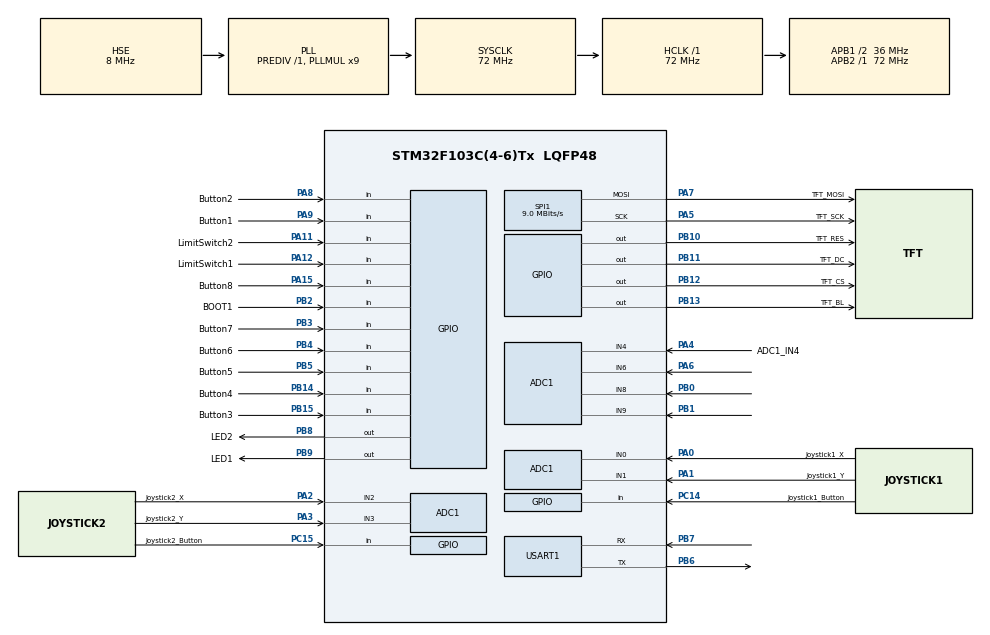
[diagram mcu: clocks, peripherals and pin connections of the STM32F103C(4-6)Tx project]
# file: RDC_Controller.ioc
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ADC1.Channel-0\#ChannelRegularConversion=ADC_CHANNEL_0
ADC1.Channel-1\#ChannelRegularConversion=ADC_CHANNEL_1
ADC1.Channel-2\#ChannelRegularConversion=ADC_CHANNEL_2
ADC1.Channel-3\#ChannelRegularConversion=ADC_CHANNEL_3
ADC1.ContinuousConvMode=ENABLE
ADC1.NbrOfConversion=4
ADC1.NbrOfConversionFlag=1
ADC1.Rank-0\#ChannelRegularConversion=1
ADC1.Rank-1\#ChannelRegularConversion=2
ADC1.Rank-2\#ChannelRegularConversion=3
ADC1.Rank-3\#ChannelRegularConversion=4
ADC1.SamplingTime-0\#ChannelRegularConversion=ADC_SAMPLETIME_1CYCLE_5
ADC1.SamplingTime-1\#ChannelRegularConversion=ADC_SAMPLETIME_1CYCLE_5
ADC1.SamplingTime-2\#ChannelRegularConversion=ADC_SAMPLETIME_1CYCLE_5
ADC1.SamplingTime-3\#ChannelRegularConversion=ADC_SAMPLETIME_1CYCLE_5
ADC1.master=1
Dma.ADC1.0.Direction=DMA_PERIPH_TO_MEMORY
Dma.ADC1.0.Instance=DMA1_Channel1
Dma.ADC1.0.MemDataAlignment=DMA_MDATAALIGN_HALFWORD
Dma.ADC1.0.MemInc=DMA_MINC_ENABLE
Dma.ADC1.0.Mode=DMA_CIRCULAR
Dma.ADC1.0.PeriphDataAlignment=DMA_PDATAALIGN_HALFWORD
Dma.ADC1.0.PeriphInc=DMA_PINC_DISABLE
Dma.ADC1.0.Priority=DMA_PRIORITY_HIGH
Dma.Request0=ADC1
Mcu.Family=STM32F1
Mcu.Name=STM32F103C(4-6)Tx
Mcu.Package=LQFP48
NVIC.PriorityGroup=NVIC_PRIORITYGROUP_4
NVIC.USART1_IRQn=true\:1\:0\:true\:false\:true\:true\:true\:true
PA0-WKUP.GPIO_Label=Joystick1_X
PA0-WKUP.Signal=ADCx_IN0
PA1.GPIO_Label=Joystick1_Y
PA1.Signal=ADCx_IN1
PA11.GPIO_Label=LimitSwitch2
PA11.GPIO_PuPd=GPIO_NOPULL
PA11.Signal=GPIO_Input
PA12.GPIO_Label=LimitSwitch1
PA12.GPIO_PuPd=GPIO_NOPULL
PA12.Signal=GPIO_Input
PA13.Mode=Serial_Wire
PA13.Signal=SYS_JTMS-SWDIO
PA14.Mode=Serial_Wire
PA14.Signal=SYS_JTCK-SWCLK
PA15.GPIO_Label=Button8
PA15.GPIO_PuPd=GPIO_PULLUP
PA15.Signal=GPIO_Input
PA2.GPIO_Label=Joystick2_X
PA2.Signal=ADCx_IN2
PA3.GPIO_Label=Joystick2_Y
PA3.Signal=ADCx_IN3
PA4.GPIO_Label=ADC1_IN4
PA4.Signal=ADCx_IN4
PA5.GPIO_Label=TFT_SCK
PA5.Mode=TX_Only_Simplex_Unidirect_Master
PA5.Signal=SPI1_SCK
PA6.Signal=ADCx_IN6
PA7.GPIO_Label=TFT_MOSI
PA7.Mode=TX_Only_Simplex_Unidirect_Master
PA7.Signal=SPI1_MOSI
PA8.GPIO_Label=Button2
PA8.GPIO_PuPd=GPIO_PULLUP
PA8.Signal=GPIO_Input
PA9.GPIO_Label=Button1
PA9.GPIO_PuPd=GPIO_PULLUP
PA9.Signal=GPIO_Input
PB0.Signal=ADCx_IN8
PB1.Signal=ADCx_IN9
PB10.GPIO_Label=TFT_RES
PB10.Signal=GPIO_Output
PB11.GPIO_Label=TFT_DC
PB11.Signal=GPIO_Output
PB12.GPIO_Label=TFT_CS
PB12.Signal=GPIO_Output
PB13.GPIO_Label=TFT_BL
PB13.Signal=GPIO_Output
PB14.GPIO_Label=Button4
PB14.GPIO_PuPd=GPIO_PULLUP
PB14.Signal=GPIO_Input
PB15.GPIO_Label=Button3
PB15.GPIO_PuPd=GPIO_PULLUP
PB15.Signal=GPIO_Input
PB2.GPIO_Label=BOOT1
PB2.Signal=GPIO_Input
PB3.GPIO_Label=Button7
PB3.GPIO_PuPd=GPIO_PULLUP
PB3.Signal=GPIO_Input
PB4.GPIO_Label=Button6
PB4.GPIO_PuPd=GPIO_PULLUP
PB4.Signal=GPIO_Input
PB5.GPIO_Label=Button5
PB5.GPIO_PuPd=GPIO_PULLUP
PB5.Signal=GPIO_Input
PB6.Mode=Asynchronous
PB6.Signal=USART1_TX
PB7.Mode=Asynchronous
PB7.Signal=USART1_RX
PB8.GPIO_Label=LED2
PB8.GPIO_PuPd=GPIO_NOPULL
PB8.PinState=GPIO_PIN_SET
PB8.Signal=GPIO_Output
PB9.GPIO_Label=LED1
PB9.GPIO_PuPd=GPIO_NOPULL
PB9.PinState=GPIO_PIN_SET
PB9.Signal=GPIO_Output
PC14-OSC32_IN.GPIO_Label=Joystick1_Button
PC14-OSC32_IN.GPIO_PuPd=GPIO_NOPULL
PC14-OSC32_IN.Signal=GPIO_Input
PC15-OSC32_OUT.GPIO_Label=Joystick2_Button
PC15-OSC32_OUT.GPIO_PuPd=GPIO_NOPULL
PC15-OSC32_OUT.Signal=GPIO_Input
PD0-OSC_IN.Mode=HSE-External-Oscillator
PD0-OSC_IN.Signal=RCC_OSC_IN
PD1-OSC_OUT.Mode=HSE-External-Oscillator
PD1-OSC_OUT.Signal=RCC_OSC_OUT
ProjectManager.HeapSize=0x200
ProjectManager.StackSize=0x400
ProjectManager.TargetToolchain=CMake
RCC.ADCPresc=RCC_ADCPCLK2_DIV6
RCC.AHBFreq_Value=72000000
RCC.APB1CLKDivider=RCC_HCLK_DIV2
RCC.APB1Freq_Value=36000000
RCC.APB1TimFreq_Value=72000000
RCC.APB2Freq_Value=72000000
RCC.APB2TimFreq_Value=72000000
RCC.HCLKFreq_Value=72000000
RCC.PLLMUL=RCC_PLL_MUL9
RCC.PLLSourceVirtual=RCC_PLLSOURCE_HSE
RCC.SYSCLKFreq_VALUE=72000000
RCC.SYSCLKSource=RCC_SYSCLKSOURCE_PLLCLK
RCC.USBFreq_Value=72000000
SH.ADCx_IN0.0=ADC1_IN0,IN0
SH.ADCx_IN1.0=ADC1_IN1,IN1
SH.ADCx_IN2.0=ADC1_IN2,IN2
SH.ADCx_IN3.0=ADC1_IN3,IN3
SH.ADCx_IN4.0=ADC1_IN4,IN4
SH.ADCx_IN6.0=ADC1_IN6,IN6
SH.ADCx_IN8.0=ADC1_IN8,IN8
SH.ADCx_IN9.0=ADC1_IN9,IN9
SPI1.BaudRatePrescaler=SPI_BAUDRATEPRESCALER_8
SPI1.CalculateBaudRate=9.0 MBits/s
SPI1.Direction=SPI_DIRECTION_2LINES
SPI1.Mode=SPI_MODE_MASTER
SPI1.VirtualType=VM_MASTER
USART1.VirtualMode=VM_ASYNC
board=custom

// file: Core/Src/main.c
/* USER CODE BEGIN Header */
/**
  ******************************************************************************
  * @file           : main.c
  * @brief          : Main program body
  ******************************************************************************
  * @attention
  *
  * Copyright (c) 2026 STMicroelectronics.
  * All rights reserved.
  *
  * This software is licensed under terms that can be found in the LICENSE file
  * in the root directory of this software component.
  * If no LICENSE file comes with this software, it is provided AS-IS.
  *
  ******************************************************************************
  */
/* USER CODE END Header */
#include "main.h"
#include "adc.h"
#include "dma.h"
#include "spi.h"
#include "usart.h"
#include "gpio.h"

/* USER CODE BEGIN Includes */
#include "lcd/lcd.h"
#include "tetris.h"

/* USER CODE END Includes */

/* USER CODE BEGIN PV */
/**
 * @brief Global game data so it can be inspected directly in the debugger.
 */
TetrisGame game;

/* USER CODE END PV */

void SystemClock_Config(void);

int main(void)
{

  /* MCU Configuration--------------------------------------------------------*/

  /* Reset of all peripherals, Initializes the Flash interface and the Systick. */
  HAL_Init();

  /* Configure the system clock */
  SystemClock_Config();

  /* Initialize all configured peripherals */
  MX_GPIO_Init();
  MX_DMA_Init();
  MX_ADC1_Init();
  MX_SPI1_Init();
  MX_USART1_UART_Init();

  /* Infinite loop */
  /* USER CODE BEGIN WHILE */
  tft_init(PIN_ON_TOP, BLACK, WHITE, CYAN, DARK_GREY);
  while (1)
  {
    /* USER CODE END WHILE */

    /* USER CODE BEGIN 3 */
    Tetris_Update(&game);
  }
  /* USER CODE END 3 */
}

void SystemClock_Config(void)
{
  RCC_OscInitTypeDef RCC_OscInitStruct = {0};
  RCC_ClkInitTypeDef RCC_ClkInitStruct = {0};
  RCC_PeriphCLKInitTypeDef PeriphClkInit = {0};

  /** Initializes the RCC Oscillators according to the specified parameters
  * in the RCC_OscInitTypeDef structure.
  */
  RCC_OscInitStruct.OscillatorType = RCC_OSCILLATORTYPE_HSE;
  RCC_OscInitStruct.HSEState = RCC_HSE_ON;
  RCC_OscInitStruct.HSEPredivValue = RCC_HSE_PREDIV_DIV1;
  RCC_OscInitStruct.HSIState = RCC_HSI_ON;
  RCC_OscInitStruct.PLL.PLLState = RCC_PLL_ON;
  RCC_OscInitStruct.PLL.PLLSource = RCC_PLLSOURCE_HSE;
  RCC_OscInitStruct.PLL.PLLMUL = RCC_PLL_MUL9;
  if (HAL_RCC_OscConfig(&RCC_OscInitStruct) != HAL_OK)
  {
    Error_Handler();
  }

  /** Initializes the CPU, AHB and APB buses clocks
  */
  RCC_ClkInitStruct.ClockType = RCC_CLOCKTYPE_HCLK|RCC_CLOCKTYPE_SYSCLK
                              |RCC_CLOCKTYPE_PCLK1|RCC_CLOCKTYPE_PCLK2;
  RCC_ClkInitStruct.SYSCLKSource = RCC_SYSCLKSOURCE_PLLCLK;
  RCC_ClkInitStruct.AHBCLKDivider = RCC_SYSCLK_DIV1;
  RCC_ClkInitStruct.APB1CLKDivider = RCC_HCLK_DIV2;
  RCC_ClkInitStruct.APB2CLKDivider = RCC_HCLK_DIV1;

  if (HAL_RCC_ClockConfig(&RCC_ClkInitStruct, FLASH_LATENCY_2) != HAL_OK)
  {
    Error_Handler();
  }
  PeriphClkInit.PeriphClockSelection = RCC_PERIPHCLK_ADC;
  PeriphClkInit.AdcClockSelection = RCC_ADCPCLK2_DIV6;
  if (HAL_RCCEx_PeriphCLKConfig(&PeriphClkInit) != HAL_OK)
  {
    Error_Handler();
  }
}

void Error_Handler(void)
{
  __disable_irq();
  while (1)
  {
  }
}
